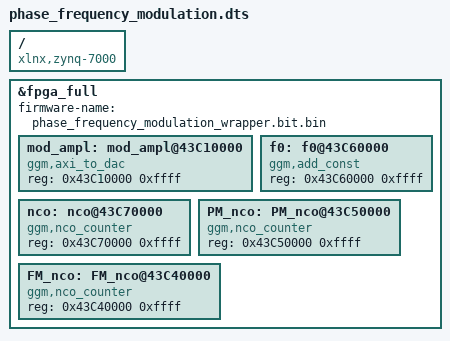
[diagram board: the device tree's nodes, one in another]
/dts-v1/;
/plugin/;

/ {
	compatible = "xlnx,zynq-7000";

	fragment0 {
		target = <&fpga_full>;
		#address-cells = <1>;
		#size-cells = <1>;
		__overlay__ {
			#address-cells = <1>;
			#size-cells = <1>;

			firmware-name = "phase_frequency_modulation_wrapper.bit.bin";

			mod_ampl: mod_ampl@43C10000{
				compatible = "ggm,axi_to_dac";
				reg = <0x43C10000 0xffff>;
			};

			f0: f0@43C60000{
				compatible = "ggm,add_const";
				reg = <0x43C60000 0xffff>;
			};

			nco: nco@43C70000{
				compatible = "ggm,nco_counter";
				reg = <0x43C70000 0xffff>;
			};

			PM_nco: PM_nco@43C50000{
				compatible = "ggm,nco_counter";
				reg = <0x43C50000 0xffff>;
			};

			FM_nco: FM_nco@43C40000{
				compatible = "ggm,nco_counter";
				reg = <0x43C40000 0xffff>;
			};

		};
	};
};
